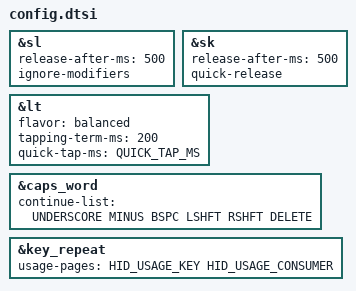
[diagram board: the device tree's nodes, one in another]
#define BASE_L 0
#define GAME_L 1
#define NAV_L 2
#define NUM_L 3
#define SYM_L 4
#define FUN_L 5

#define QUICK_TAP_MS 175

#define MEH LS(LA(LCTRL))
#define HYPR LG(LS(LA(LCTRL)))
#define ME(key) LS(LA(LC(key)))
#define HP(key) LG(LS(LA(LC(key))))

&sl { 
  release-after-ms = <500>;
  ignore-modifiers;
};

&sk {
    release-after-ms = <500>;
    quick-release;
};

&lt {  // layer-tap config
    flavor = "balanced";
    tapping-term-ms = <200>;
    quick-tap-ms = <QUICK_TAP_MS>;
};

&caps_word {
    /delete-property/ ignore-modifiers;
  continue-list = <UNDERSCORE MINUS BSPC LSHFT RSHFT DELETE>;
};

&key_repeat {
    usage-pages = <HID_USAGE_KEY HID_USAGE_CONSUMER>;
};


/* &num_word {  // num-word, requires PR #1441 */
/*     layers = <NUM_L>; */
/* }; */
